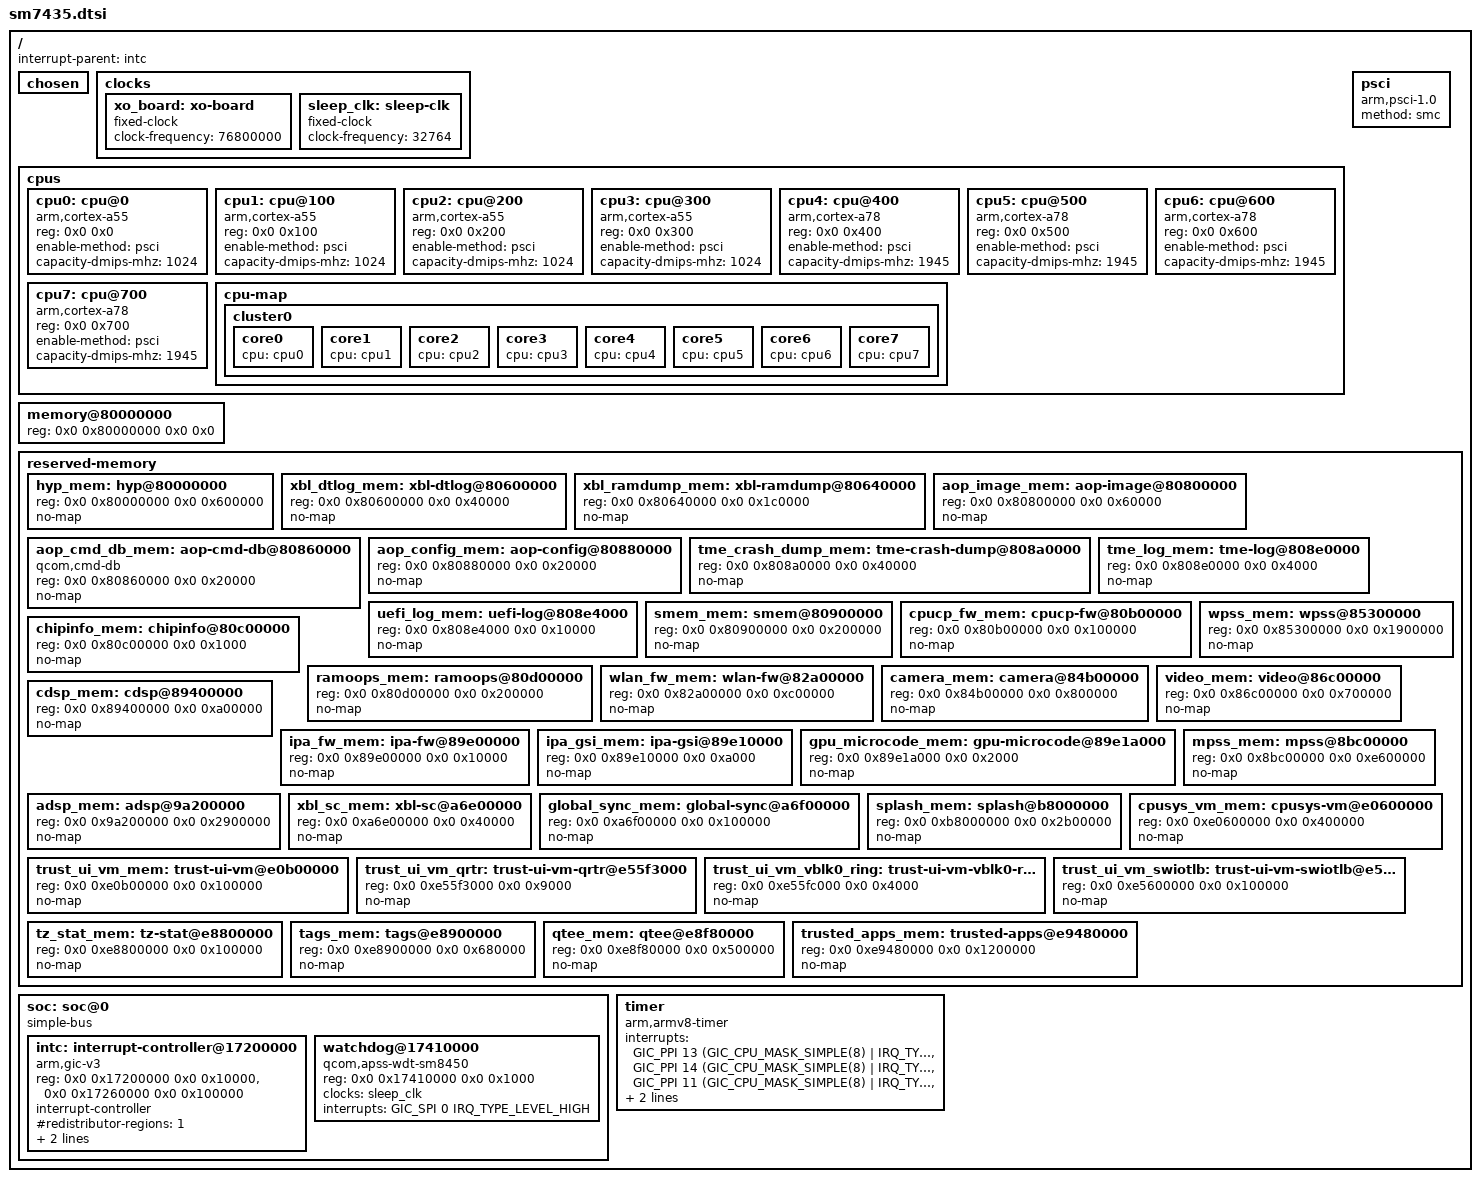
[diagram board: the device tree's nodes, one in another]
// SPDX-License-Identifier: BSD-3-Clause
/*
 * Qualcomm SM7435 (parrot), minimal: CPUs, GIC, timer, watchdog.
 * Addresses from the Xiaomi ruan 5.10 device tree.
 */

#include <dt-bindings/interrupt-controller/arm-gic.h>

/ {
	interrupt-parent = <&intc>;

	#address-cells = <2>;
	#size-cells = <2>;

	chosen { };

	clocks {
		xo_board: xo-board {
			compatible = "fixed-clock";
			#clock-cells = <0>;
			clock-frequency = <76800000>;
		};

		sleep_clk: sleep-clk {
			compatible = "fixed-clock";
			#clock-cells = <0>;
			clock-frequency = <32764>;
		};
	};

	cpus {
		#address-cells = <2>;
		#size-cells = <0>;

		cpu0: cpu@0 {
			device_type = "cpu";
			compatible = "arm,cortex-a55";
			reg = <0x0 0x0>;
			enable-method = "psci";
			capacity-dmips-mhz = <1024>;
		};

		cpu1: cpu@100 {
			device_type = "cpu";
			compatible = "arm,cortex-a55";
			reg = <0x0 0x100>;
			enable-method = "psci";
			capacity-dmips-mhz = <1024>;
		};

		cpu2: cpu@200 {
			device_type = "cpu";
			compatible = "arm,cortex-a55";
			reg = <0x0 0x200>;
			enable-method = "psci";
			capacity-dmips-mhz = <1024>;
		};

		cpu3: cpu@300 {
			device_type = "cpu";
			compatible = "arm,cortex-a55";
			reg = <0x0 0x300>;
			enable-method = "psci";
			capacity-dmips-mhz = <1024>;
		};

		cpu4: cpu@400 {
			device_type = "cpu";
			compatible = "arm,cortex-a78";
			reg = <0x0 0x400>;
			enable-method = "psci";
			capacity-dmips-mhz = <1945>;
		};

		cpu5: cpu@500 {
			device_type = "cpu";
			compatible = "arm,cortex-a78";
			reg = <0x0 0x500>;
			enable-method = "psci";
			capacity-dmips-mhz = <1945>;
		};

		cpu6: cpu@600 {
			device_type = "cpu";
			compatible = "arm,cortex-a78";
			reg = <0x0 0x600>;
			enable-method = "psci";
			capacity-dmips-mhz = <1945>;
		};

		cpu7: cpu@700 {
			device_type = "cpu";
			compatible = "arm,cortex-a78";
			reg = <0x0 0x700>;
			enable-method = "psci";
			capacity-dmips-mhz = <1945>;
		};

		cpu-map {
			cluster0 {
				core0 { cpu = <&cpu0>; };
				core1 { cpu = <&cpu1>; };
				core2 { cpu = <&cpu2>; };
				core3 { cpu = <&cpu3>; };
				core4 { cpu = <&cpu4>; };
				core5 { cpu = <&cpu5>; };
				core6 { cpu = <&cpu6>; };
				core7 { cpu = <&cpu7>; };
			};
		};
	};

	/* The bootloader fills in the size. */
	memory@80000000 {
		device_type = "memory";
		reg = <0x0 0x80000000 0x0 0x0>;
	};

	psci {
		compatible = "arm,psci-1.0";
		method = "smc";
	};

	reserved-memory {
		#address-cells = <2>;
		#size-cells = <2>;
		ranges;

		hyp_mem: hyp@80000000 { reg = <0x0 0x80000000 0x0 0x600000>; no-map; };
		xbl_dtlog_mem: xbl-dtlog@80600000 { reg = <0x0 0x80600000 0x0 0x40000>; no-map; };
		xbl_ramdump_mem: xbl-ramdump@80640000 { reg = <0x0 0x80640000 0x0 0x1c0000>; no-map; };
		aop_image_mem: aop-image@80800000 { reg = <0x0 0x80800000 0x0 0x60000>; no-map; };
		aop_cmd_db_mem: aop-cmd-db@80860000 {
			compatible = "qcom,cmd-db";
			reg = <0x0 0x80860000 0x0 0x20000>;
			no-map;
		};
		aop_config_mem: aop-config@80880000 { reg = <0x0 0x80880000 0x0 0x20000>; no-map; };
		tme_crash_dump_mem: tme-crash-dump@808a0000 { reg = <0x0 0x808a0000 0x0 0x40000>; no-map; };
		tme_log_mem: tme-log@808e0000 { reg = <0x0 0x808e0000 0x0 0x4000>; no-map; };
		uefi_log_mem: uefi-log@808e4000 { reg = <0x0 0x808e4000 0x0 0x10000>; no-map; };
		smem_mem: smem@80900000 { reg = <0x0 0x80900000 0x0 0x200000>; no-map; };
		cpucp_fw_mem: cpucp-fw@80b00000 { reg = <0x0 0x80b00000 0x0 0x100000>; no-map; };
		chipinfo_mem: chipinfo@80c00000 { reg = <0x0 0x80c00000 0x0 0x1000>; no-map; };
		ramoops_mem: ramoops@80d00000 { reg = <0x0 0x80d00000 0x0 0x200000>; no-map; };
		wlan_fw_mem: wlan-fw@82a00000 { reg = <0x0 0x82a00000 0x0 0xc00000>; no-map; };
		camera_mem: camera@84b00000 { reg = <0x0 0x84b00000 0x0 0x800000>; no-map; };
		wpss_mem: wpss@85300000 { reg = <0x0 0x85300000 0x0 0x1900000>; no-map; };
		video_mem: video@86c00000 { reg = <0x0 0x86c00000 0x0 0x700000>; no-map; };
		cdsp_mem: cdsp@89400000 { reg = <0x0 0x89400000 0x0 0xa00000>; no-map; };
		ipa_fw_mem: ipa-fw@89e00000 { reg = <0x0 0x89e00000 0x0 0x10000>; no-map; };
		ipa_gsi_mem: ipa-gsi@89e10000 { reg = <0x0 0x89e10000 0x0 0xa000>; no-map; };
		gpu_microcode_mem: gpu-microcode@89e1a000 { reg = <0x0 0x89e1a000 0x0 0x2000>; no-map; };
		mpss_mem: mpss@8bc00000 { reg = <0x0 0x8bc00000 0x0 0xe600000>; no-map; };
		adsp_mem: adsp@9a200000 { reg = <0x0 0x9a200000 0x0 0x2900000>; no-map; };
		xbl_sc_mem: xbl-sc@a6e00000 { reg = <0x0 0xa6e00000 0x0 0x40000>; no-map; };
		global_sync_mem: global-sync@a6f00000 { reg = <0x0 0xa6f00000 0x0 0x100000>; no-map; };
		splash_mem: splash@b8000000 { reg = <0x0 0xb8000000 0x0 0x2b00000>; no-map; };
		cpusys_vm_mem: cpusys-vm@e0600000 { reg = <0x0 0xe0600000 0x0 0x400000>; no-map; };
		trust_ui_vm_mem: trust-ui-vm@e0b00000 { reg = <0x0 0xe0b00000 0x0 0x100000>; no-map; };
		trust_ui_vm_qrtr: trust-ui-vm-qrtr@e55f3000 { reg = <0x0 0xe55f3000 0x0 0x9000>; no-map; };
		trust_ui_vm_vblk0_ring: trust-ui-vm-vblk0-ring@e55fc000 { reg = <0x0 0xe55fc000 0x0 0x4000>; no-map; };
		trust_ui_vm_swiotlb: trust-ui-vm-swiotlb@e5600000 { reg = <0x0 0xe5600000 0x0 0x100000>; no-map; };
		tz_stat_mem: tz-stat@e8800000 { reg = <0x0 0xe8800000 0x0 0x100000>; no-map; };
		tags_mem: tags@e8900000 { reg = <0x0 0xe8900000 0x0 0x680000>; no-map; };
		qtee_mem: qtee@e8f80000 { reg = <0x0 0xe8f80000 0x0 0x500000>; no-map; };
		trusted_apps_mem: trusted-apps@e9480000 { reg = <0x0 0xe9480000 0x0 0x1200000>; no-map; };
	};

	soc: soc@0 {
		compatible = "simple-bus";
		#address-cells = <2>;
		#size-cells = <2>;
		ranges = <0 0 0 0 0x10 0>;

		intc: interrupt-controller@17200000 {
			compatible = "arm,gic-v3";
			reg = <0x0 0x17200000 0x0 0x10000>,
			      <0x0 0x17260000 0x0 0x100000>;
			#interrupt-cells = <3>;
			interrupt-controller;
			#redistributor-regions = <1>;
			redistributor-stride = <0x0 0x20000>;
			interrupts = <GIC_PPI 9 IRQ_TYPE_LEVEL_HIGH>;
		};

		/* Left running by the bootloader: bites ~20 s after boot unless petted. */
		watchdog@17410000 {
			compatible = "qcom,apss-wdt-sm8450", "qcom,kpss-wdt";
			reg = <0x0 0x17410000 0x0 0x1000>;
			clocks = <&sleep_clk>;
			interrupts = <GIC_SPI 0 IRQ_TYPE_LEVEL_HIGH>;
		};
	};

	timer {
		compatible = "arm,armv8-timer";
		interrupts = <GIC_PPI 13 (GIC_CPU_MASK_SIMPLE(8) | IRQ_TYPE_LEVEL_LOW)>,
			     <GIC_PPI 14 (GIC_CPU_MASK_SIMPLE(8) | IRQ_TYPE_LEVEL_LOW)>,
			     <GIC_PPI 11 (GIC_CPU_MASK_SIMPLE(8) | IRQ_TYPE_LEVEL_LOW)>,
			     <GIC_PPI 12 (GIC_CPU_MASK_SIMPLE(8) | IRQ_TYPE_LEVEL_LOW)>;
		clock-frequency = <19200000>;
	};
};
